# RX64M_FLASH_Pilot register map
File version: 1.0
RX64M_FLASH_Pilot peripheral registers generated from iodefine.h (pilot).
Registers are 16-bit, read-write, reset 0x0 unless marked. A register's access mark holds for its fields unless they carry their own. Offsets are from the block's base; lines under a group give offsets from that group; [hi:lo] are bit positions; {n}, {i} and the like mark numbered series; 'fields as' and 'values as' point back to an identical list; <NAME> marks a mode.

## Memory map
0x0008C294 FLASH size 0x771E52

## FLASH
Base 0x0008C294
0x02 FWEPROR 8-bit reset 0x2
  [1:0] FLWE
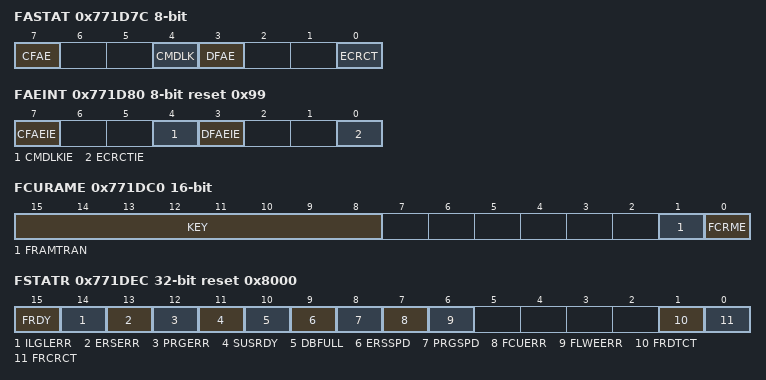
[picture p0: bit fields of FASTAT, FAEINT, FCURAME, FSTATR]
0x771D7C FASTAT 8-bit
  [7] CFAE, [4] CMDLK, [3] DFAE, [0] ECRCT
0x771D80 FAEINT 8-bit reset 0x99
  [7] CFAEIE, [4] CMDLKIE, [3] DFAEIE, [0] ECRCTIE
0x771D84 FRDYIE 8-bit
  [0] FRDYIE
0x771D9C FSADDR 32-bit
0x771DA0 FEADDR 32-bit
0x771DC0 FCURAME
  [15:8] KEY, [1] FRAMTRAN, [0] FCRME
0x771DEC FSTATR 32-bit reset 0x8000
  [15] FRDY, [14] ILGLERR, [13] ERSERR, [12] PRGERR, [11] SUSRDY, [10] DBFULL, [9] ERSSPD, [8] PRGSPD, [7] FCUERR, [6] FLWEERR, [1] FRDTCT, [0] FRCRCT
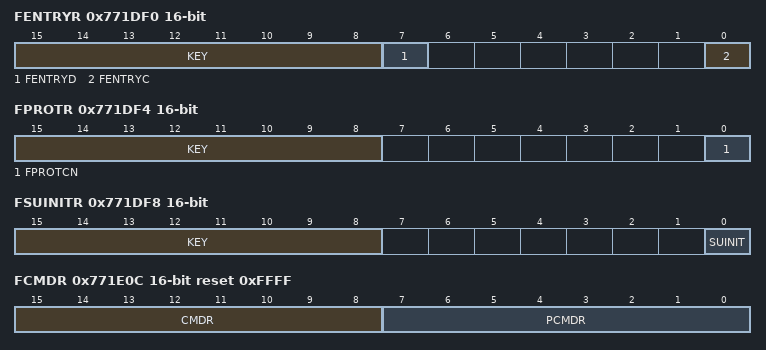
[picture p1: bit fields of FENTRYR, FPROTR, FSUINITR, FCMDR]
0x771DF0 FENTRYR
  [15:8] KEY, [7] FENTRYD, [0] FENTRYC
0x771DF4 FPROTR
  [15:8] KEY, [0] FPROTCN
0x771DF8 FSUINITR
  [15:8] KEY, [0] SUINIT
0x771DFC FLKSTAT 8-bit
  [0] FLOCKST
0x771E0C FCMDR ro reset 0xFFFF
  [15:8] CMDR, [7:0] PCMDR
0x771E2C FPESTAT
  [7:0] PEERRST
0x771E3C FBCCNT 8-bit
  [0] BCDIR
0x771E40 FBCSTAT 8-bit
  [0] BCST
0x771E44 FPSADDR 32-bit reset 0x8000
  [18:0] PSADR
0x771E4C FCPSR
  [0] ESUSPMD
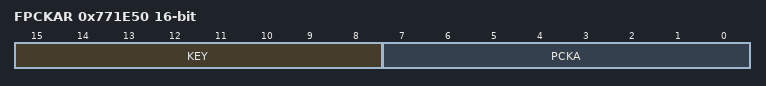
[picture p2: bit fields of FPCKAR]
0x771E50 FPCKAR (reset mask 0xFF00)
  [15:8] KEY, [7:0] PCKA
